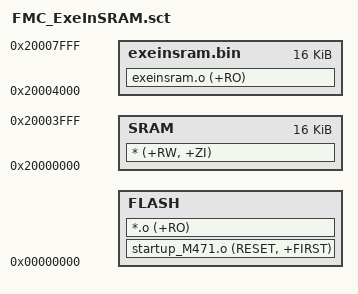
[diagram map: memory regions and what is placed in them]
LOAD_ROM  0x0
{
    FLASH  +0
    {
        startup_M471.o (RESET, +FIRST)
        *.o (+RO)
    }

    SRAM  0x20000000 0x4000
    {
        * (+RW, +ZI)
    }

    exeinsram.bin 0x20004000 0x4000
    {
        exeinsram.o (+RO)
    }
}

